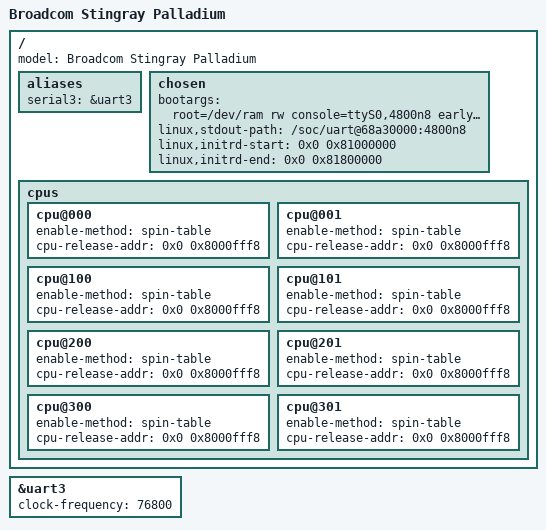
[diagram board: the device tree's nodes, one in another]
/*
 *  BSD LICENSE
 *
 *  Copyright(c) 2015 Broadcom Corporation.  All rights reserved.
 *
 *  Redistribution and use in source and binary forms, with or without
 *  modification, are permitted provided that the following conditions
 *  are met:
 *
 *    * Redistributions of source code must retain the above copyright
 *      notice, this list of conditions and the following disclaimer.
 *    * Redistributions in binary form must reproduce the above copyright
 *      notice, this list of conditions and the following disclaimer in
 *      the documentation and/or other materials provided with the
 *      distribution.
 *    * Neither the name of Broadcom Corporation nor the names of its
 *      contributors may be used to endorse or promote products derived
 *      from this software without specific prior written permission.
 *
 *  THIS SOFTWARE IS PROVIDED BY THE COPYRIGHT HOLDERS AND CONTRIBUTORS
 *  "AS IS" AND ANY EXPRESS OR IMPLIED WARRANTIES, INCLUDING, BUT NOT
 *  LIMITED TO, THE IMPLIED WARRANTIES OF MERCHANTABILITY AND FITNESS FOR
 *  A PARTICULAR PURPOSE ARE DISCLAIMED. IN NO EVENT SHALL THE COPYRIGHT
 *  OWNER OR CONTRIBUTORS BE LIABLE FOR ANY DIRECT, INDIRECT, INCIDENTAL,
 *  SPECIAL, EXEMPLARY, OR CONSEQUENTIAL DAMAGES (INCLUDING, BUT NOT
 *  LIMITED TO, PROCUREMENT OF SUBSTITUTE GOODS OR SERVICES; LOSS OF USE,
 *  DATA, OR PROFITS; OR BUSINESS INTERRUPTION) HOWEVER CAUSED AND ON ANY
 *  THEORY OF LIABILITY, WHETHER IN CONTRACT, STRICT LIABILITY, OR TORT
 *  (INCLUDING NEGLIGENCE OR OTHERWISE) ARISING IN ANY WAY OUT OF THE USE
 * OF THIS SOFTWARE, EVEN IF ADVISED OF THE POSSIBILITY OF SUCH DAMAGE.
 */

/dts-v1/;

/* HACK: Reserve arm64 tiny boot location */
/memreserve/ 0x80000000 0x00020000;
/* HACK: Reserve initrd location */
/memreserve/ 0x81000000 0x00800000;

#include "stingray.dtsi"

/ {
	model = "Broadcom Stingray Palladium";

	aliases {
		serial3 = &uart3;
	};

	chosen { /* HACK: hard-code kernel args and initrd location */
		bootargs = "root=/dev/ram rw console=ttyS0,4800n8 \
			    earlycon=uart8250,mmio32,0x68a30000";
		linux,stdout-path = "/soc/uart@68a30000:4800n8";
		linux,initrd-start = <0x0 0x81000000>;
		linux,initrd-end = <0x0 0x81800000>;
	};

	cpus { /* HACK: arm64 tiny boot implements spin-table */
		cpu@000 {
			enable-method = "spin-table";
			cpu-release-addr = <0x0 0x8000fff8>;
		};

		cpu@001 {
			enable-method = "spin-table";
			cpu-release-addr = <0x0 0x8000fff8>;
		};

		cpu@100 {
			enable-method = "spin-table";
			cpu-release-addr = <0x0 0x8000fff8>;
		};

		cpu@101 {
			enable-method = "spin-table";
			cpu-release-addr = <0x0 0x8000fff8>;
		};

		cpu@200 {
			enable-method = "spin-table";
			cpu-release-addr = <0x0 0x8000fff8>;
		};

		cpu@201 {
			enable-method = "spin-table";
			cpu-release-addr = <0x0 0x8000fff8>;
		};

		cpu@300 {
			enable-method = "spin-table";
			cpu-release-addr = <0x0 0x8000fff8>;
		};

		cpu@301 {
			enable-method = "spin-table";
			cpu-release-addr = <0x0 0x8000fff8>;
		};
	};
};

&uart3 {
	/* Hack: For palladium we force DLL=1 and DLM=0.
	 * To achieve this, we set:
	 * clock-frequency = <desired_baudrate> x 16
	 */
	clock-frequency = <76800>;
	status = "ok";
};
